# HDSC_HC32M423 register map
Vendor: HDSC Co.,Ltd.; Series: ARMCM4; File version: 1.0
CPU: CM4 r0p1, little endian, MPU, FPU, 4 interrupt priority bits
Registers are 32-bit, read-write, reset 0x0 unless marked. A register's access mark holds for its fields unless they carry their own. Offsets are from the block's base; [hi:lo] are bit positions; {n}, {i} and the like mark numbered series.

## EMU
Base 0x40054000
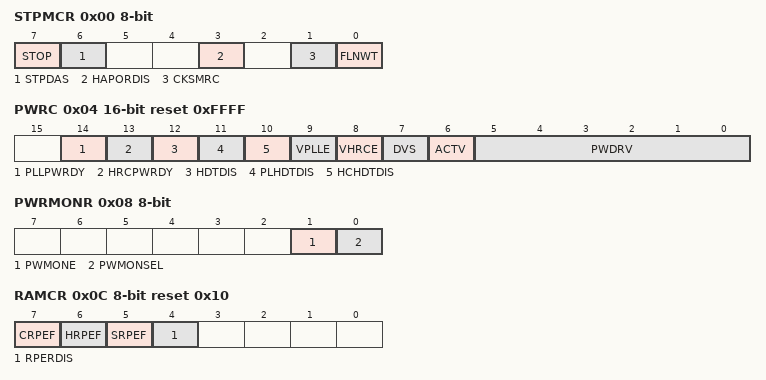
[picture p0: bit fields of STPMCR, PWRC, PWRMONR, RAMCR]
0x00 STPMCR 8-bit
  [7] STOP, [6] STPDAS, [3] HAPORDIS, [1] CKSMRC, [0] FLNWT
0x04 PWRC 16-bit reset 0xFFFF
  [14] PLLPWRDY, [13] HRCPWRDY, [12] HDTDIS, [11] PLHDTDIS, [10] HCHDTDIS, [9] VPLLE, [8] VHRCE, [7] DVS, [6] ACTV, [5:0] PWDRV
0x08 PWRMONR 8-bit
  [1] PWMONE, [0] PWMONSEL
0x0C RAMCR 8-bit reset 0x10
  [7] CRPEF, [6] HRPEF, [5] SRPEF, [4] RPERDIS
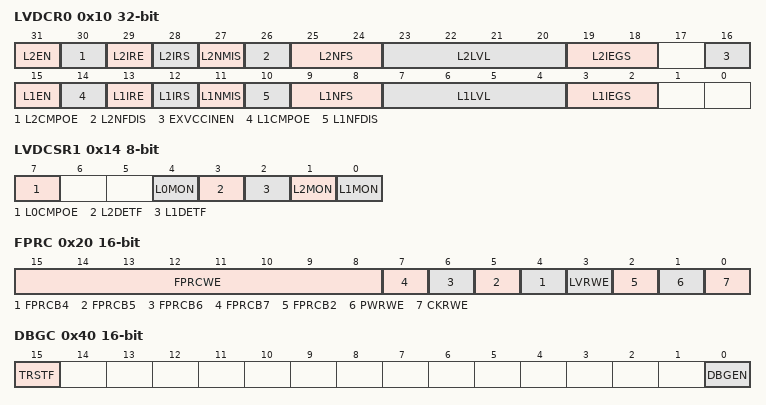
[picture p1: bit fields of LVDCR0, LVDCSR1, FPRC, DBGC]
0x10 LVDCR0
  [31] L2EN, [30] L2CMPOE, [29] L2IRE, [28] L2IRS, [27] L2NMIS, [26] L2NFDIS, [25:24] L2NFS, [23:20] L2LVL, [19:18] L2IEGS, [16] EXVCCINEN, [15] L1EN, [14] L1CMPOE, [13] L1IRE, [12] L1IRS, [11] L1NMIS, [10] L1NFDIS, [9:8] L1NFS, [7:4] L1LVL, [3:2] L1IEGS
0x14 LVDCSR1 8-bit ro
  [7] L0CMPOE rw, [4] L0MON rw, [3] L2DETF rw, [2] L1DETF rw, [1] L2MON, [0] L1MON
0x20 FPRC 16-bit
  [15:8] FPRCWE wo, [n] FPRCB{n} (n=4..7), [3] LVRWE, [2] FPRCB2, [1] PWRWE, [0] CKRWE
0x40 DBGC 16-bit
  [15] TRSTF, [0] DBGEN
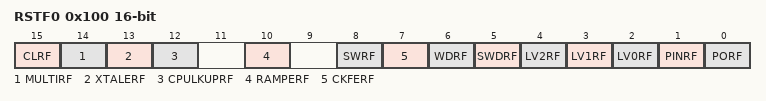
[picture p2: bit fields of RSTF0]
0x100 RSTF0 16-bit
  [15] CLRF, [14] MULTIRF, [13] XTALERF, [12] CPULKUPRF, [10] RAMPERF, [8] SWRF, [7] CKFERF, [6] WDRF, [5] SWDRF, [4] LV2RF, [3] LV1RF, [2] LV0RF, [1] PINRF, [0] PORF

## FCM
Base 0x40048400
0x00 LVR
  [15:0] LVR
0x04 UVR
  [15:0] UVR
0x08 CNTR ro
  [15:0] CNTR
0x0C STR
  [0] START
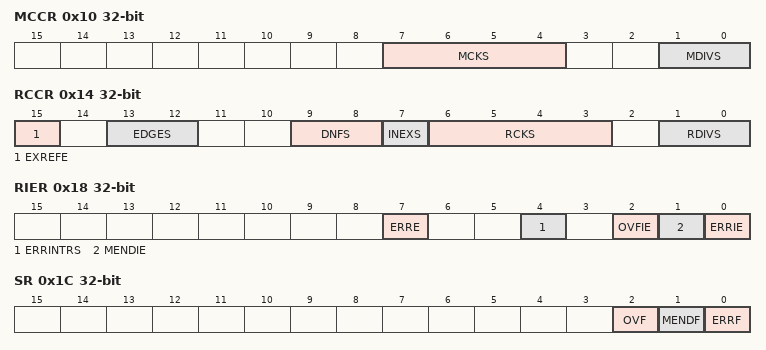
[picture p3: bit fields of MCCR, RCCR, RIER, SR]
0x10 MCCR
  [7:4] MCKS, [1:0] MDIVS
0x14 RCCR
  [15] EXREFE, [13:12] EDGES, [9:8] DNFS, [7] INEXS, [6:3] RCKS, [1:0] RDIVS
0x18 RIER
  [7] ERRE, [4] ERRINTRS, [2] OVFIE, [1] MENDIE, [0] ERRIE
0x1C SR ro
  [2] OVF, [1] MENDF, [0] ERRF
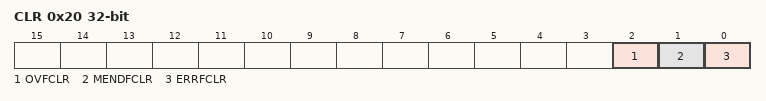
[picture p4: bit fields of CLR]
0x20 CLR wo
  [2] OVFCLR, [1] MENDFCLR, [0] ERRFCLR

## I2C
Base 0x4004E000
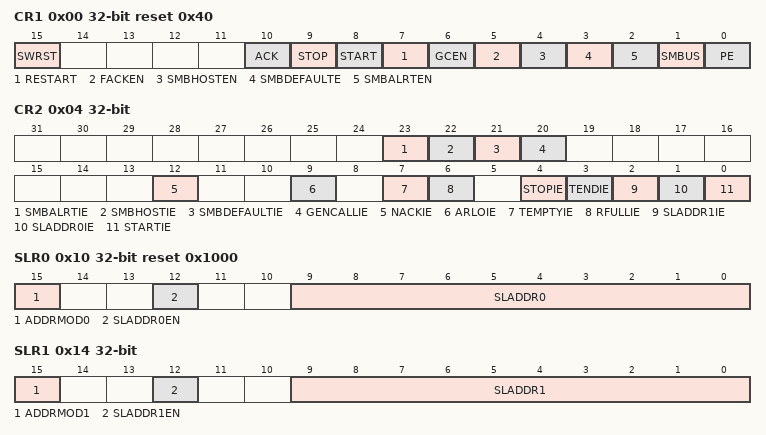
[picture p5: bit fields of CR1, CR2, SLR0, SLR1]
0x00 CR1 reset 0x40
  [15] SWRST, [10] ACK, [9] STOP, [8] START, [7] RESTART, [6] GCEN, [5] FACKEN, [4] SMBHOSTEN, [3] SMBDEFAULTE, [2] SMBALRTEN, [1] SMBUS, [0] PE
0x04 CR2
  [23] SMBALRTIE, [22] SMBHOSTIE, [21] SMBDEFAULTIE, [20] GENCALLIE, [12] NACKIE, [9] ARLOIE, [7] TEMPTYIE, [6] RFULLIE, [4] STOPIE, [3] TENDIE, [2] SLADDR1IE, [1] SLADDR0IE, [0] STARTIE
0x10 SLR0 reset 0x1000
  [15] ADDRMOD0, [12] SLADDR0EN, [9:0] SLADDR0
0x14 SLR1
  [15] ADDRMOD1, [12] SLADDR1EN, [9:0] SLADDR1
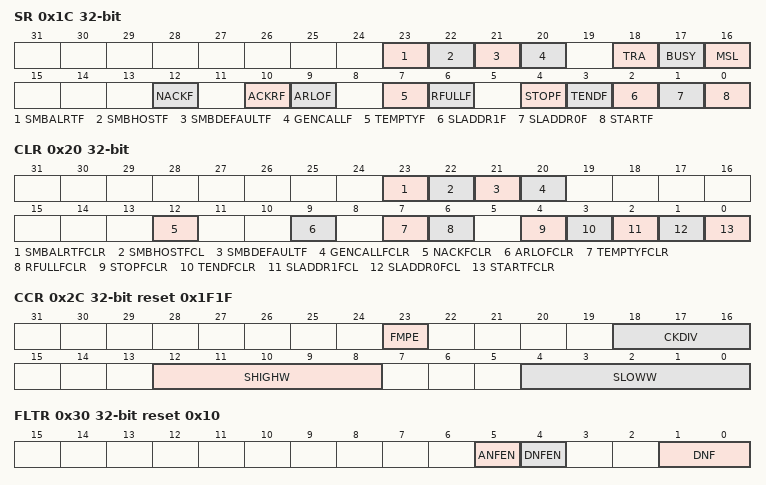
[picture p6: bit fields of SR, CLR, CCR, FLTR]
0x1C SR ro
  [23] SMBALRTF, [22] SMBHOSTF, [21] SMBDEFAULTF, [20] GENCALLF, [18] TRA rw, [17] BUSY, [16] MSL rw, [12] NACKF, [10] ACKRF, [9] ARLOF, [7] TEMPTYF, [6] RFULLF, [4] STOPF, [3] TENDF, [2] SLADDR1F, [1] SLADDR0F, [0] STARTF
0x20 CLR wo
  [23] SMBALRTFCLR, [22] SMBHOSTFCL, [21] SMBDEFAULTF, [20] GENCALLFCLR, [12] NACKFCLR, [9] ARLOFCLR, [7] TEMPTYFCLR, [6] RFULLFCLR, [4] STOPFCLR, [3] TENDFCLR, [2] SLADDR1FCL, [1] SLADDR0FCL, [0] STARTFCLR
0x24 DTR reset 0xFF
  [7:0] DT
0x28 DRR
  [7:0] DR
0x2C CCR reset 0x1F1F
  [23] FMPE, [18:16] CKDIV, [12:8] SHIGHW, [4:0] SLOWW
0x30 FLTR reset 0x10
  [5] ANFEN, [4] DNFEN, [1:0] DNF

## ICG
Base 0x00000240
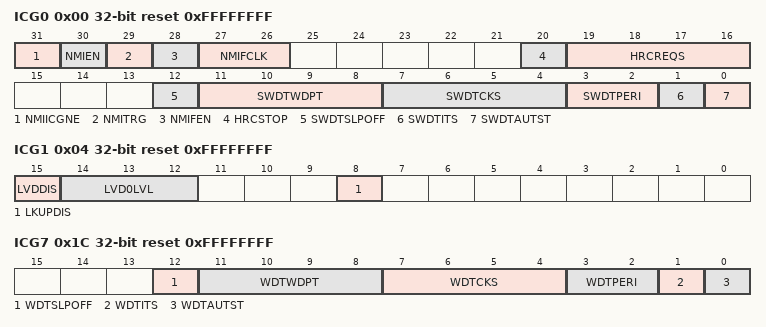
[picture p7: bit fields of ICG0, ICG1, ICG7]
0x00 ICG0 ro reset 0xFFFFFFFF
  [31] NMIICGNE, [30] NMIEN, [29] NMITRG, [28] NMIFEN, [27:26] NMIFCLK, [20] HRCSTOP rw, [19:16] HRCREQS, [12] SWDTSLPOFF, [11:8] SWDTWDPT, [7:4] SWDTCKS, [3:2] SWDTPERI, [1] SWDTITS, [0] SWDTAUTST
0x04 ICG1 ro reset 0xFFFFFFFF
  [15] LVDDIS, [14:12] LVD0LVL, [8] LKUPDIS
{0x0+4i} ICG{i} reset 0xFFFFFFFF (i=2..6)
0x1C ICG7 ro reset 0xFFFFFFFF
  [12] WDTSLPOFF, [11:8] WDTWDPT, [7:4] WDTCKS, [3:2] WDTPERI, [1] WDTITS, [0] WDTAUTST

## RMU
Base 0x40054100
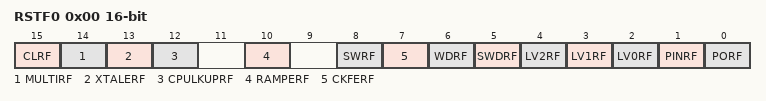
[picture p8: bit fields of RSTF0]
0x00 RSTF0 16-bit
  [15] CLRF, [14] MULTIRF, [13] XTALERF, [12] CPULKUPRF, [10] RAMPERF, [8] SWRF, [7] CKFERF, [6] WDRF, [5] SWDRF, [4] LV2RF, [3] LV1RF, [2] LV0RF, [1] PINRF, [0] PORF

## SPI
Base 0x4001C000
0x00 DR
  [15:0] SPD
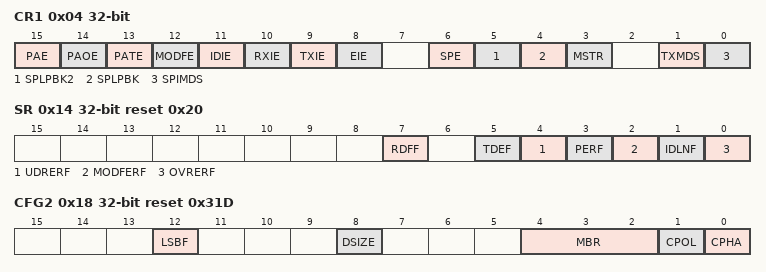
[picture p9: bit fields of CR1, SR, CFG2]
0x04 CR1
  [15] PAE, [14] PAOE, [13] PATE, [12] MODFE, [11] IDIE, [10] RXIE, [9] TXIE, [8] EIE, [6] SPE, [5] SPLPBK2, [4] SPLPBK, [3] MSTR, [1] TXMDS, [0] SPIMDS
0x0C CFG1 reset 0x10
  [8] SS0PV
0x14 SR reset 0x20
  [7] RDFF, [5] TDEF, [4] UDRERF, [3] PERF, [2] MODFERF, [1] IDLNF ro, [0] OVRERF
0x18 CFG2 reset 0x31D
  [12] LSBF, [8] DSIZE, [4:2] MBR, [1] CPOL, [0] CPHA
